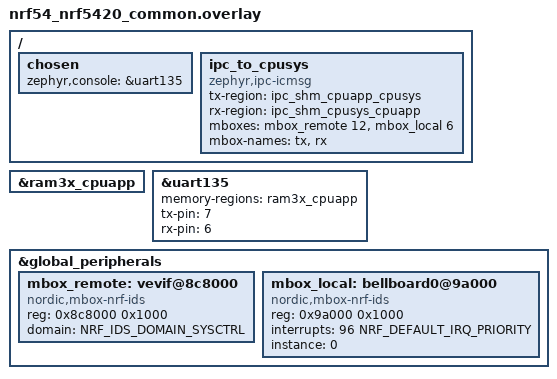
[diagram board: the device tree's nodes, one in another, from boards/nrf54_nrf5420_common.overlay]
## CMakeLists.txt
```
# SPDX-License-Identifier: Apache-2.0

cmake_minimum_required(VERSION 3.20.0)

find_package(Zephyr REQUIRED HINTS $ENV{ZEPHYR_BASE})
project(nrf_temp_sensor)

FILE(GLOB app_sources src/*.c)
target_sources(app PRIVATE ${app_sources})
```

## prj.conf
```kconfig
CONFIG_ZTEST=y

# Temp sensor
CONFIG_SENSOR=y
CONFIG_TEMP_NRF5=y
```

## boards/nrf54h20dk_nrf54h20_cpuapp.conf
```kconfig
# NRFS configuration
CONFIG_NRFS=y
CONFIG_NRFS_LOCAL_DOMAIN=y
CONFIG_NRFS_BACKEND_IPC_SERVICE=y
# With logging enabled memory usage is higher
CONFIG_NRFS_BACKEND_TX_TASK_STACK_SIZE=2048

# IPC configuration
CONFIG_IPC_SERVICE=y
CONFIG_IPC_SERVICE_BACKEND_ICMSG=y
CONFIG_MBOX=y
CONFIG_MBOX_NRFX_IDS=y

# Misc
CONFIG_NRF_REGTOOL_VERBOSE_ON=y
```

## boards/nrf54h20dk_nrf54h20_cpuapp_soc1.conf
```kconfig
#
# Copyright (c) 2022 Nordic Semiconductor ASA
#
# SPDX-License-Identifier: LicenseRef-BSD-5-Clause-Nordic
#

CONFIG_MBOX_NRFX_IDS=y

# Logging
CONFIG_LOG=y
CONFIG_LOG_MODE_IMMEDIATE=y
CONFIG_CONSOLE=y
CONFIG_SERIAL=y
CONFIG_UART_CONSOLE=y
CONFIG_STDOUT_CONSOLE=y
CONFIG_PRINTK=y

# NRFS configuration
CONFIG_NRFS=y
CONFIG_NRFS_LOCAL_DOMAIN=y
CONFIG_NRFS_BACKEND_IPC_SERVICE=y
CONFIG_NRFS_BACKEND_RX_TASK_STACK_SIZE=2048
CONFIG_NRFS_BACKEND_TX_TASK_STACK_SIZE=2048
```

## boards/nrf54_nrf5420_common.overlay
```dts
/*
 * Copyright (c) 2022, Nordic Semiconductor ASA
 *
 * SPDX-License-Identifier: Apache-2.0
 */

 #include <common/nordic_nrf_next/nrfx_ram3x_dma.dtsi>

 /{
	chosen {
		/delete-property/ nordic,bellboard-cpuapp;
		/delete-property/ nordic,bellboard-cpurad;
		/delete-property/ nordic,bellboard-cpusec;
		zephyr,console = &uart135;
	};

	ipc_to_cpusys: ipc_to_cpusys {
		compatible = "zephyr,ipc-icmsg";
		tx-region = <&ipc_shm_cpuapp_cpusys>;
		rx-region = <&ipc_shm_cpusys_cpuapp>;
		mboxes = <&mbox_remote 12>,
			 <&mbox_local 6>;
		mbox-names = "tx", "rx";
		status = "okay";
	};
};

/* ram3x_cpuapp buffer is used by App core UART driver. */
&ram3x_cpuapp {
	status = "okay";
};

&uart135 {
	status = "okay";
	memory-regions = <&ram3x_cpuapp>;
	tx-pin = <7>;
	rx-pin = <6>;
};

&global_peripherals {
	/delete-node/ bellboard@9a000;
	/delete-node/ vevif@8c8000;
	/delete-node/ vevif@8d4000;
	/delete-node/ vevif@908000;

	mbox_remote: vevif@8c8000 {
		compatible = "nordic,mbox-nrf-ids";
		reg = <0x8c8000 0x1000>;
		domain = <NRF_IDS_DOMAIN_SYSCTRL>;
		status = "okay";
		#mbox-cells = <1>;
	};

	mbox_local: bellboard0@9a000 {
		compatible = "nordic,mbox-nrf-ids";
		reg = <0x9a000 0x1000>;
		interrupts = <96 NRF_DEFAULT_IRQ_PRIORITY>;
		instance = <0>;
		status = "okay";
		#mbox-cells = <1>;
	};
};
```

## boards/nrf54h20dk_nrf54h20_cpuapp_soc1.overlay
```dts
/*
 * Copyright (c) 2022 Nordic Semiconductor ASA
 *
 * SPDX-License-Identifier: LicenseRef-BSD-5-Clause-Nordic
 */

#include <common/nordic_nrf_next/nrfx_ram3x_dma.dtsi>

/{
    chosen {
        zephyr,console = &uart136;
    };

    ipc_to_cpusys: ipc_to_cpusys {
        compatible = "zephyr,ipc-icmsg";
        tx-region = <&ipc_shm_cpuapp_cpusys>;
        rx-region = <&ipc_shm_cpusys_cpuapp>;
        mboxes = <&mbox_remote 12>,
             <&bellboard_cpuapp 6>;
        mbox-names = "tx", "rx";
        status = "okay";
    };
};

&ram3x_cpuapp {
    status = "okay";
};

&uart136 {
    status = "okay";
    memory-regions = <&ram3x_cpuapp>;
};

&global_peripherals {
    /delete-node/ vevif@8c8000;
    /delete-node/ vevif@8d4000;
    /delete-node/ vevif@908000;

    mbox_remote: vevif@8c8000 {
        compatible = "nordic,mbox-nrf-ids";
        reg = <0x8c8000 0x1000>;
        domain = <NRF_IDS_DOMAIN_SYSCTRL>;
        status = "okay";
        #mbox-cells = <1>;
    };
};
```

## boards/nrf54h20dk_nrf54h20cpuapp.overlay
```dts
/*
 * Copyright (c) 2022, Nordic Semiconductor ASA
 *
 * SPDX-License-Identifier: Apache-2.0
 */

 #include <common/nordic_nrf_next/nrfx_ram3x_dma.dtsi>

 /{
    chosen {
        /delete-property/ nordic,bellboard-cpuapp;
        /delete-property/ nordic,bellboard-cpurad;
        /delete-property/ nordic,bellboard-cpusec;
        zephyr,console = &uart135;
    };

    ipc_to_cpusys: ipc_to_cpusys {
        compatible = "zephyr,ipc-icmsg";
        tx-region = <&ipc_shm_cpuapp_cpusys>;
        rx-region = <&ipc_shm_cpusys_cpuapp>;
        mboxes = <&mbox_remote 12>,
             <&mbox_local 6>;
        mbox-names = "tx", "rx";
        status = "okay";
    };
};

/* ram3x_cpuapp buffer is used by App core UART driver. */
&ram3x_cpuapp {
    status = "okay";
};

&uart135 {
    status = "okay";
    memory-regions = <&ram3x_cpuapp>;
};

&global_peripherals {
    /delete-node/ bellboard@9a000;
    /delete-node/ vevif@8c8000;
    /delete-node/ vevif@8d4000;
    /delete-node/ vevif@908000;

    mbox_remote: vevif@8c8000 {
        compatible = "nordic,mbox-nrf-ids";
        reg = <0x8c8000 0x1000>;
        domain = <NRF_IDS_DOMAIN_SYSCTRL>;
        status = "okay";
        #mbox-cells = <1>;
    };

    mbox_local: bellboard0@9a000 {
        compatible = "nordic,mbox-nrf-ids";
        reg = <0x9a000 0x1000>;
        interrupts = <96 NRF_DEFAULT_IRQ_PRIORITY>;
        instance = <0>;
        status = "okay";
        #mbox-cells = <1>;
    };
};
```

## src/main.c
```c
/*
 * Copyright (c) 2022, Nordic Semiconductor ASA
 *
 * SPDX-License-Identifier: Apache-2.0
 */

#include <zephyr/ztest.h>
#include <zephyr/device.h>
#include <zephyr/drivers/sensor.h>

#if defined(CONFIG_HAS_NRF_TEMP_NRFS)
#define TEMP_SENSOR_NODE_ID       DT_NODELABEL(temp_nrfs)
#else
#define TEMP_SENSOR_NODE_ID       DT_NODELABEL(temp)
#endif

void test_temp_driver_test(void)
{
	const struct device *temp_dev = DEVICE_DT_GET(TEMP_SENSOR_NODE_ID);

	zassert_not_null(temp_dev, "Device object is NULL.");
	zassert_true(device_is_ready(temp_dev), "Device is not ready.");

	int rc = 0;
	int retry_cnt = 0;
	while ((rc = sensor_sample_fetch(temp_dev)) == -ENOTCONN) {
		k_sleep(K_MSEC(1000));
		retry_cnt++;
		zassert_false(retry_cnt >= 3, "Backend connection fail.");
	}

	zassert_ok(rc, "Cannot fetch a sample from temperature sensor.");

	struct sensor_value val;
	sensor_value_from_double(&val, 0);
	zassert_ok(sensor_channel_get(temp_dev, SENSOR_CHAN_DIE_TEMP, &val), "Get temperature fail.");
#if !defined(CONFIG_NO_ANALOG_PART)
	double temp_val = sensor_value_to_double(&val);
	zassert_true(temp_val > -40, "Temperature out of range %d [C]", temp_val);
#endif

	zassert_ok(sensor_sample_fetch(temp_dev), "Cannot fetch a sample from temperature sensor.");

	sensor_value_from_double(&val, 0);
	zassert_ok(sensor_channel_get(temp_dev, SENSOR_CHAN_DIE_TEMP, &val), "Get temperature fail.");
#if !defined(CONFIG_NO_ANALOG_PART)
	temp_val = sensor_value_to_double(&val);
	zassert_true(temp_val > -40, "Temperature out of range %d [C]", temp_val);
#endif
}

void test_main(void)
{
	ztest_test_suite(test_temp_driver,
			 ztest_unit_test(test_temp_driver_test)
			 );
	ztest_run_test_suite(test_temp_driver);
}
```
